# RTS5918 register map
Vendor: Realtek Semiconductor Corp.; Series: RTS5918 Series; File version: 1.00
CPU: ARMV8MML r0p0, little endian, MPU, FPU, VTOR, 3 interrupt priority bits, 8 SAU regions
Registers are 32-bit, read-write, reset 0x0 unless marked. A register's access mark holds for its fields unless they carry their own. Offsets are from the block's base; [hi:lo] are bit positions; {n}, {i} and the like mark numbered series; 'fields as' and 'values as' point back to an identical list.

## LEDDBG0 — LED Debug 0
Base 0x4000F930
Same registers: LEDDBG1 0x4000F944
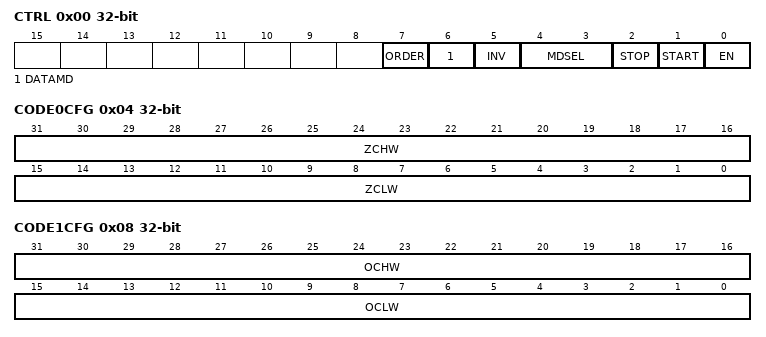
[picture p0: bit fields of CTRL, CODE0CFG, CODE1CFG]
0x00 CTRL — LED DEBUG CONTROL REGISTER
  [7] ORDER — BIT TRANSFER ORDER
    0=MSB (MSB First); 1=LSB (LSB First)
  [6] DATAMD — LED Debug Data Mode
    0=ONE (1 Byte Mode); 1=TWO (2 Byte Mode)
  [5] INV — Inverse Idle Ouput
    0=NONE (Default Low); 1=INVERT (Default High); 2=ALWAYS (Always Run Mode)
  [4:3] MDSEL — LED DEBUG MODE SELECT
    0=ONESHOT (One Shot Mode); 1=CONTINUE (Continous Mode)
  [2] STOP — LED DEBUG STOP
    0=NONE (No effect); 1=STOP
  [1] START — LED START
    0=NONE (No effect); 1=START (LED debug start)
  [0] EN — LED DEBUG ENABLE
    0=DISABLE (Disable LED debug); 1=ENABLE (Enable LED debug)
0x04 CODE0CFG — LEDDBG 0 CODE PERIOD REGISTER
  [31:16] ZCHW — LED Debug 0 Code High Width
  [15:0] ZCLW — LED Debug 0 Code Low Width
0x08 CODE1CFG — LEDDBG 1 CODE PERIOD REGISTER
  [31:16] OCHW — LED Debug 1 High Width
  [15:0] OCLW — LED Debug 1 Low Width
0x0C IDLEDLY — LEDSTP IDLE DELAY REGISTER
0x10 DATA — LEDDBG DATA REGISTER

## MICROCNT — Micro Counter Controller
Base 0x40255400
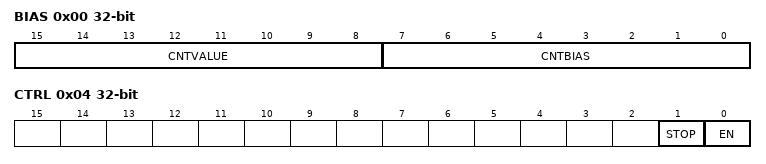
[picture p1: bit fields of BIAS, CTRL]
0x00 BIAS
  [15:8] CNTVALUE — Micro Counter Value
  [7:0] CNTBIAS — Micro Counter Bias
0x04 CTRL
  [1] STOP — Micro Counter Stop
    0=RUNNING (Micro Counter Running); 1=STOP (Enable Micro Stop)
  [0] EN — Micro Counter Enable
    0=DISABLE (Disable Micro Counter); 1=ENABLE (Enable Micro Counter)

## CEC — CEC Controller
Base 0x40254000
Same registers: CEC1 0x40254100
0x00 TXFIFO wo — TX DATA FIFO REGISTER
  [7:0] DATA — TX Data FIFO
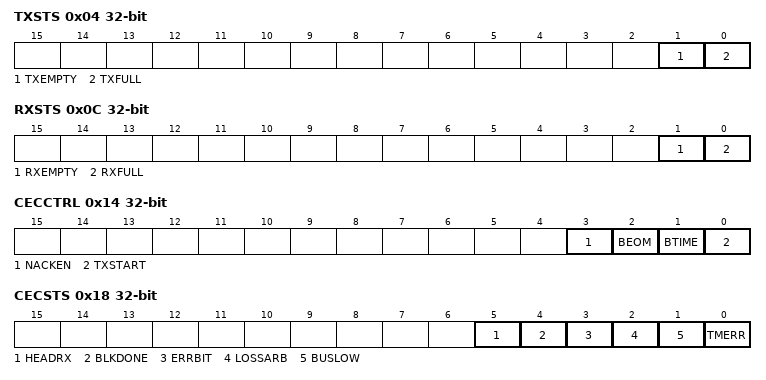
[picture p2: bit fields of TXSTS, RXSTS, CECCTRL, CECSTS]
0x04 TXSTS ro — TX FIFO STATUS REGISTER
  [1] TXEMPTY — TX FIFO Empty
    0=NOTEMPTY (TX FIFO is not EMPTY); 1=EMPTY (TX FIFO is EMPTY)
  [0] TXFULL — TX FIFO Full
    0=NOTFULL (TX FIFO is not FULL); 1=FULL (TX FIFO is FULL)
0x08 RXFIFO ro — RX DATA FIFO REGISTER
  [7:0] DATA — RX Data FIFO
0x0C RXSTS ro — RX FIFO STATUS REGISTER
  [1] RXEMPTY — RX FIFO Empty
    0=NOTEMPTY (RX FIFO is not EMPTY); 1=EMPTY (RX FIFO is EMPTY)
  [0] RXFULL — RX FIFO Full
    0=NOTFULL (RX FIFO is not FULL); 1=FULL (RX FIFO is FULL)
0x10 CECADDR — CEC LOGICAL ADDRESS REGISTER
  [3:0] ADDR — CEC Logical Address
0x14 CECCTRL — CEC CONTROL REGISTER
  [3] NACKEN — NACK Enable
    0=ACK; 1=NACK
  [2] BEOM — CEC EOM Bit
    0=NONE; 1=SET (EOM Bit)
  [1] BTIME — CEC Bit Timing
    0=NONE; 1=SET (Add Timing)
  [0] TXSTART — CEC TC Start
    0=NONE; 1=START (TX Start)
0x18 CECSTS — CEC STATUS REGISTER
  [5] HEADRX write-1-clears — CEC Header Recived
    0=NOT_OCCURRED (CEC Header Not Recived); 1=OCCURRED (CEC Header Recived)
  [4] BLKDONE write-1-clears — CEC Block Done
    0=NOT_OCCURRED (CEC TX/RX Block Not Done); 1=OCCURRED (CEC TX/RX Block Done)
  [3] ERRBIT write-1-clears — CEC Error Bit Notified
    0=NOT_OCCURRED (CEC without Error Bit); 1=OCCURRED (CEC with Error Bit)
  [2] LOSSARB write-1-clears — CEC Loss Arbitration
    0=NOT_OCCURRED (CEC Not Loss Arbitration); 1=OCCURRED (CEC Loss Arbitration)
  [1] BUSLOW write-1-clears — CEC Bus Low
    0=NOT_OCCURRED (CEC Bus Low Error Not Occurred); 1=OCCURRED (CEC Bus Low Error Occurred)
  [0] TMERR write-1-clears — CEC Bit Timing Error
    0=NOT_OCCURRED (CEC Bit Timing Error Not Occurred); 1=OCCURRED (CEC Bit Timing Error Occurred)
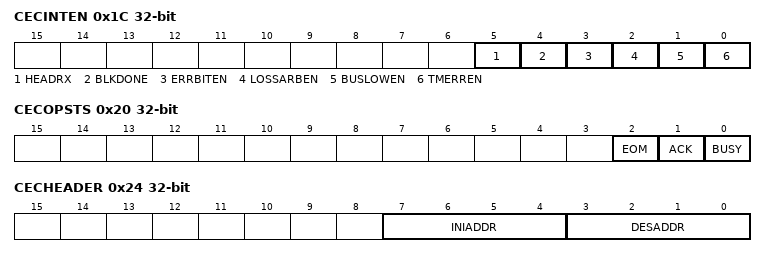
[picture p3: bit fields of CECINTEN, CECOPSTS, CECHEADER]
0x1C CECINTEN — CEC INTERRUPT ENABLE REGISTER
  [5] HEADRX — CEC Header Recived Interrupt Enable
    0=DISABLE (CEC Header Recived Interrupt Disable); 1=Enable (CEC Header Recived Interrupt Enable)
  [4] BLKDONE — CEC Block Done Interrupt Enable
    0=DISABLE (CEC TX/RX Block Done Interrupt Disable); 1=Enable (CEC TX/RX Block Done Interrupt Enable)
  [3] ERRBITEN — CEC Error Bit Notified Interrupt Enable
    0=DISABLE (CEC with Error Bit Interrupt Disable); 1=Enable (CEC with Error Bit Interrupt Enable)
  [2] LOSSARBEN — CEC Loss Arbitration Interrupt Enable
    0=DISABLE (CEC Loss Arbitration Interrupt Disable); 1=Enable (CEC Loss Arbitration Interrupt Enable)
  [1] BUSLOWEN — CEC Bus Low Interrupt Enable
    0=DISABLE (CEC Bus Low Error Interrupt Disable); 1=Enable (CEC Bus Low Error Interrupt Enable)
  [0] TMERREN — CEC Bit Timing Error Interrupt Enable
    0=DISABLE (CEC Bit Timing Error Interrupt Disable); 1=Enable (EC Bit Timing Error Interrupt Enable)
0x20 CECOPSTS ro — CEC OPERATION STATUS REGISTER
  [2] EOM — EOM Status in Header Block
    0=LOW (EOM Asserted); 1=HIGH (EOM Not Asserted)
  [1] ACK — ACK Status from Follower
    0=LOW (ACK is Low); 1=HIGH (ACK is High)
  [0] BUSY — CEC In Process
    0=IDLE (CEC Bus is Idle); 1=BUSY (CEC Bus is Busy)
0x24 CECHEADER ro
  [7:4] INIADDR — Initiator Address
  [3:0] DESADDR — Destination Address

## I2CDBGCTRL — I2C Debug Controller
Base 0x40251C00
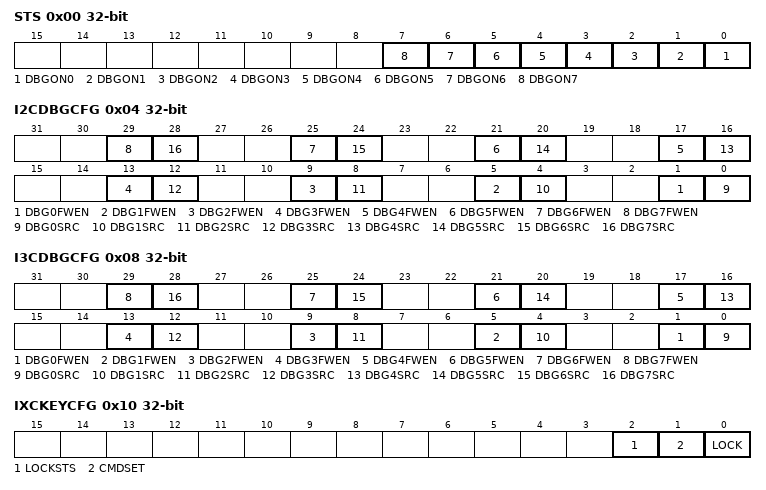
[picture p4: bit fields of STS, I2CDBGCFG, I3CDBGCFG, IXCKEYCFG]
0x00 STS — STATUS REGISTER
  [all] fields
    0=OFF (Debug Off); 1=ON (Debug On)
  [n] DBGON{n} (n=0..7) — Debug On
0x04 I2CDBGCFG — I2C DEBUG CONFIGURATION REGISTER
  [4n+1] DBG{n}FWEN (n=0..7) — Debug Firmware Setting
    0=DISABLE (Firmware Disable); 1=ENABLE (Firmware Enable)
  [4n] DBG{n}SRC (n=0..7) — Debug Setting Source
    0=HW (Source from Hardware); 1=SW (Source from Firmware)
0x08 I3CDBGCFG — I3C DEBUG CONFIGURATION REGISTER
  fields as I2CDBGCFG
0x0C I3CDBGINT — I3C DEBUG INTERRUPT REGISTER
  [0] INTEN — I3CDBGINT
0x10 IXCKEYCFG — I2C/I3C PROTECTION KEY CONFIGURATION REGISTER
  [2] LOCKSTS ro — Lock Status
    0=UNLOCKED; 1=LOCKED
  [1] CMDSET — Set Lock Command
    0=NONE; 1=SET
  [0] LOCK — Lock Access to SPIC
    0=UNLOCKED (Unlock Access to SPIC); 1=LOCKED (Lock Access to SPIC)
0x14 UNLOCKKEYH — UNLOCKED KEY HIGH 4 BYTE REGISTER
0x18 UNLOCKKEYL — UNLOCKED KEY LOW 4 BYTE REGISTER
0x1C LOCKKEYH — LOCKED KEY HIGH 4 BYTE REGISTER
0x20 LOCKKEYL — LOCKED KEY LOW 4 BYTE REGISTER
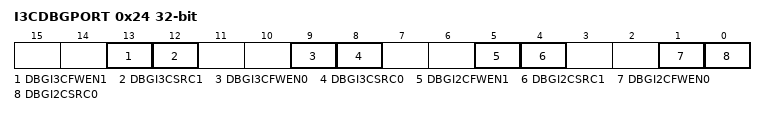
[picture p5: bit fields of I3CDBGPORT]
0x24 I3CDBGPORT — I3C PORT DEBUG CONFIGURATION REGISTER
  [13] DBGI3CFWEN1 — Debug I3C Firmware Setting I3C1 Port
    0=DISABLE (Firmware Disable); 1=ENABLE (Firmware Enable)
  [12] DBGI3CSRC1 — Debug I3C Setting I3C1 Port Source
    0=HW (Source from Hardware); 1=SW (Source from Firmware)
  [9] DBGI3CFWEN0 — Debug I3C Firmware Setting I3C0 Port
    0=DISABLE (Firmware Disable); 1=ENABLE (Firmware Enable)
  [8] DBGI3CSRC0 — Debug I3C Setting I3C0 Port Source
    0=HW (Source from Hardware); 1=SW (Source from Firmware)
  [5] DBGI2CFWEN1 — Debug I2C Firmware Setting I3C1 Port
    0=DISABLE (Firmware Disable); 1=ENABLE (Firmware Enable)
  [4] DBGI2CSRC1 — Debug I2C Setting I3C1 Port Source
    0=HW (Source from Hardware); 1=SW (Source from Firmware)
  [1] DBGI2CFWEN0 — Debug I2C Firmware Setting I3C0 Port
    0=DISABLE (Firmware Disable); 1=ENABLE (Firmware Enable)
  [0] DBGI2CSRC0 — Debug I2C Setting I3C0 Port Source
    0=HW (Source from Hardware); 1=SW (Source from Firmware)

## BRAM — Battery RAM
Base 0x20200000
Same registers: TRAM 0x40255600
{0x0+i} BYTE[{i}] (i=0..255) 8-bit — BYTE DATA

## USBOTG1
Base 0x50000000
Same registers: LALU 0x40050000, LALU2 0x40090000, PUF 0x400D0000, LED 0x40252D00, LED2 0x40252E00, LED3 0x40252F00, LED4 0x40253000, LPT 0x40255300, PUFOTP 0x40264000, USBOTG2 0x50040000
0x00 RESERVE — BYTE DATA
